# tviic2d6mddr register map
Vendor: Cypress Semiconductor; Series: tviic2d6mddr; File version: 1.0
CPU: CM7 r0p1, little endian, MPU, FPU, VTOR, 3 interrupt priority bits
Registers are 32-bit, read-write, reset 0x0 unless marked. A register's access mark holds for its fields unless they carry their own. Offsets are from the block's base; [hi:lo] are bit positions; lines under a group give offsets from that group; {n}, {i} and the like mark numbered series; 'fields as' and 'values as' point back to an identical list.

## VIDEOSS0 (part 3 of 18) — Video and Graphics Subsystem IP
Base 0x40A00000
0x00 SUBSS group — Sub Interface
  0x40000 GFX2D group — Graphics 2D Core
    0x20000 BLITENG group — Blit Engine
      0x4800 FETCHMASK group — Fetch MASK (only for IBO)
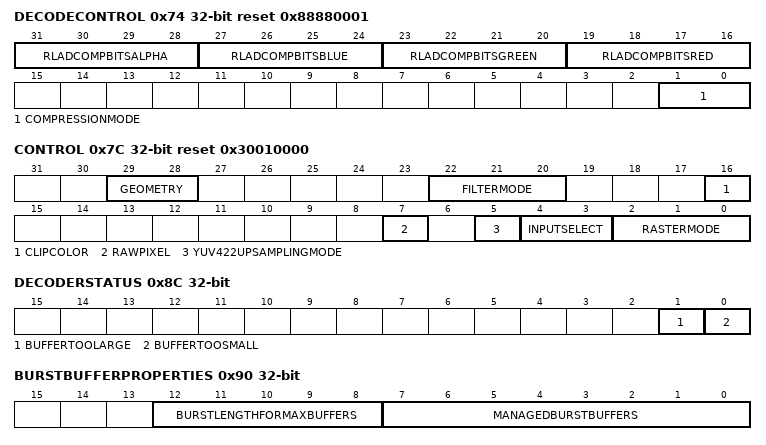
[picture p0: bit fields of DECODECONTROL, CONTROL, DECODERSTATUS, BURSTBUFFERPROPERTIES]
        0x74 DECODECONTROL reset 0x88880001 — Control options for RLAD decompression.
          [31:28] RLADCOMPBITSALPHA — Maximum for average number of bits per compressed pixel for Alpha channel. This must match the corresponding encoder setting.
          [27:24] RLADCOMPBITSBLUE — Maximum for average number of bits per compressed pixel for Blue or V (chroma) channel. This must match the corresponding encoder setting.
          [23:20] RLADCOMPBITSGREEN — Maximum for average number of bits per compressed pixel for Green or U (chroma) channel. This must match the corresponding encoder setting.
          [19:16] RLADCOMPBITSRED — Maximum for average number of bits per compressed pixel for Red or Y (luma) channel. This must match the corresponding encoder setting.
          [1:0] COMPRESSIONMODE — Algorithm that the encoder used for compression.
            0=RLAD (Run-Length Adaptive Dithering (lossy compression).); 1=RLAD_UNIFORM (Run-Length Adaptive Dithering (lossy compression; uniform package size).); 2=RLA (Run-Length Adaptive (lossless compression).); 3=RL (Standard Run-Length. In contrary to other modes is in big endian format.)
        0x78 SOURCEBUFFERLENGTH — Source buffer length for compressed data.
          [28:0] RLEWORDS — Number of 32-bit words minus one that are required to decode the run length encoded source buffer.
        0x7C CONTROL reset 0x30010000 — Shared common control settings for all layers.
          [29:28] GEOMETRY — Control the geomety settings (PerspStartX/Y/W and PerspDeltaXX/XY/YX/YY/XW/YW usage) for the raster mode PERSPECTIVE.
            0=TRANSLATE (PerspStartX/Y are used. (PerspDeltaXY/YX/XW/YW are 0. PerspDeltaXX/YY and PerspStartW are 1.)); 1=SCALE (PerspStartX/Y and PerspDeltaXX/YY are used. (PerspDeltaXY/YX/XW/YW are 0. PerspStartW is 1.)); 2=ROTATION (PerspStartX/Y and PerspDeltaXX/XY/YX/YY are used. (PerspDeltaXW/YW are 0. PerspStartW is 1.)); 3=PERSPECTIVE (All values PerspStartX/Y/W and PerspDeltaXX/XY/YX/YY/XW/YW are used)
          [22:20] FILTERMODE — Use this to select between nearest and bilinear filtering. Only has an effect if rastermode == ARBITRARY or rastermode == PERSPECTIVE or rastermode == AFFINE.
            0=NEAREST (Chooses pixel closest to sample point); 1=BILINEAR (Calculates result from 4 pixels closest to sample point); 2=FIR2 (FIR mode with 2 programmable pixel positions and coefficients); 3=FIR4 (FIR mode with 4 programmable pixel positions and coefficients); 4=HOR_LINEAR (Calculates result from 2 pixels closest to the sample point and on the same line)
          [16] CLIPCOLOR — Selects which color to take for pixels that do not lie inside the clip window of any layer.
            0=NULL (Null color.); 1=LAYER (Color of layer number given by ClipLayer (or layer 0 when Fetch unit has one layer only). The color is then the layer's source or tiling color.)
          [7] RAWPIXEL — Raw pixel mode. If enabled (value = 1), the ComponentBits/Shift settings are replaced for all layers by fixed values that allow passing the pixel data read from memory unchanged to subsequent units (e.g. for reading coordinate layers). Multiply stages and transparent color are deactivated. Skip and Tile pixels are not affected by this setting.
          [5] YUV422UPSAMPLINGMODE — Selects a method for horizontal up-sampling of YUV 422/420 input data.
            0=REPLICATE (Replicate mode for interspersed samples (UV samples between Y samples).); 1=INTERPOLATE (Interpolate mode for coaligned samples (UV samples at Y sample positions).)
          [4:3] INPUTSELECT — Selects function for the frame input port.
            0=INACTIVE (Not used.); 1=COMPPACK (Used for component packing (e.g. UV or source alpha buffer).); 2=ALPHAMASK (Used for RGB and alpha pre-multiply stage (mask alpha buffer).); 3=COORDINATE (Used for arbitrary warping (coordinate buffer).)
          [2:0] RASTERMODE — Selects a method how to generate source buffer sample points.
            0=NORMAL ([IBO only, for LBO use PERSPECTIVE with corresponding Geometry] First sample at StartX/Y relative to origin. Hor/ver increments using DeltaX/Y and DeltaSwap setup.); 1=DECODE ([FetchDecode/FetchBlit only] Source buffer is an encoded bit stream. First sample at origin (0,0). Hor/ver increments = (1,0)/(0,1).); 2=ARBITRARY ([FetchBlit/Warp only] Arbitrary warping (filter is active). Coordinates are read from frame input port. InputSelect must be set to COORDINATE. ArbStartX/Y and ArbDeltaXX/XY/YX/YY must be setup.); 3=PERSPECTIVE ([FetchBlit only] Affine/Perspective warping (filter is active). First sample at PerspStartX/Y/W. Hor/ver increments using PerspDeltaXX/XY/YX/YY/WX/WY. Homogeneous coordinates. See also field Geometry to reduce coordinate amount.); 4=YUV422 ([FetchBlit/Decode only] Source buffer is packed YUV 422. First sample at origin (0,0). Hor/ver increments = (1,0)/(0,1). All correllated window widths and horizontal offsets must be even.)
        0x80 CONTROLTRIGGER wo reset not defined — Shadow load trigger.
          [0] SHDTOKGEN — Writing a 1 to this will load shadow registers into the active configuration with the next start of frame and send a shadow load token to subsequent units.
        0x84 START wo reset not defined — Frame start trigger.
          [0] START — Writing a 1 to this field will start generating one frame (for debugging purposes only).
        0x88 FETCHTYPE ro reset not defined — Fetch unit type.
          [3:0] FETCHTYPE — This field can be used to determine what kind of fetch unit this is.
            0=DECODE (Fetch unit with RL and RLAD decoder.); 1=LAYER (Fetch unit with fractional plane (8 layers).); 2=WARP (Fetch unit with arbitrary warping and fractional plane (8 layers).); 3=ECO (Fetch unit with minimum feature set for alpha, chroma and coordinate planes.); 4=PERSP (Fetch unit with affine, perspective and arbitrary warping.); 5=ROT (Fetch unit with affine and arbitrary warping.); 6=DECODEL (Fetch unit with RL and RLAD decoder, reduced feature set.); 7=LAYERL (Fetch unit with fractional plane (8 layers), reduced feature set.); 8=ROTL (Fetch unit with affine and arbitrary warping, reduced feature set.); 9=ECOL (Fetch unit with reduced minimum feature set for alpha, chroma and coordinate planes.); 10=BLIT (Fetch unit with DECODE and PERSP capabilities.)
        0x8C DECODERSTATUS — Status information of the RLAD decoder.
          [1] BUFFERTOOLARGE — The buffer size given by RLEWords is too large. A complete output frame could be decoded, but more data was read than necessary.
          [0] BUFFERTOOSMALL — The buffer size given by RLEWords is too small. No complete output frame could be decoded.
        0x90 BURSTBUFFERPROPERTIES ro reset not defined
          [12:8] BURSTLENGTHFORMAXBUFFERS — Maximum Burst Length that can be used when ManagedBurstBuffers burst buffers are used.
          [7:0] MANAGEDBURSTBUFFERS — Maximum number of burst buffers that can be administrated in the AXI interface.
      0x5000 ROP group
        0x00 STATICCONTROL — Raster Operation static control register
          [0] SHDEN — Enables shadowing of all RWS type registers (0=write_through, 1=shadowed).
        0x04 CONTROL — Raster Operation control register
          [10] TERTDIV2 — Selects whether to divide the tertiary input color components by two or not for ADD mode. This field has no effect on a color component in ROP mode.
            0=BYPASS (No change to input); 1=DIVIDEBY2 (Input is divided by two/shift to the right by one)
          [9] SECDIV2 — Selects whether to divide the secondary input color components by two or not for ADD mode. This field has no effect on a color component in ROP mode.
            values as TERTDIV2
          [8] PRIMDIV2 — Selects whether to divide the primary input color components by two or not for ADD mode. This field has no effect on a color component in ROP mode.
            values as TERTDIV2
          [7] REDMODE — Selects the mode for the red component channel, has no effect in NEUTRAL mode
            0=ROP (Normal raster operation mode, using the operation index); 1=ADD (Add mode, adds this component from all enabled inputs, clamps to 1)
          [6] GREENMODE — Selects the mode for the green component channel, has no effect in NEUTRAL mode
            values as REDMODE
          [5] BLUEMODE — Selects the mode for the blue component channel, has no effect in NEUTRAL mode
            values as REDMODE
          [4] ALPHAMODE — Selects the mode for the alpha component channel, has no effect in NEUTRAL mode
            values as REDMODE
          [0] MODE — Operation mode for rop
            0=NEUTRAL (Neutral mode); 1=OPERATION (Normal Operation)
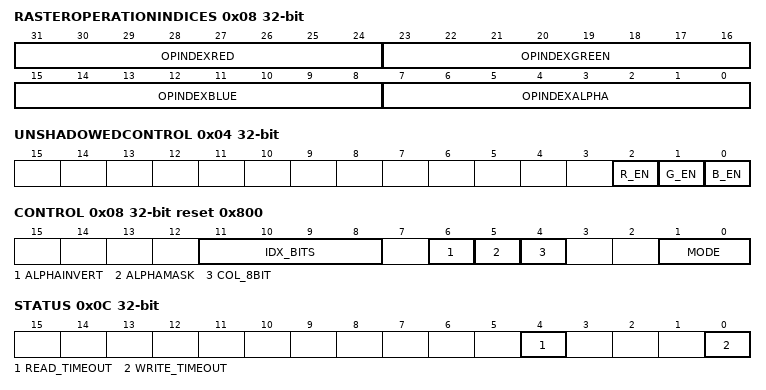
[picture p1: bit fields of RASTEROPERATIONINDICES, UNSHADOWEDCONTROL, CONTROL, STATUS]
        0x08 RASTEROPERATIONINDICES — ROP operation indices
          [31:24] OPINDEXRED — Red operation index
          [23:16] OPINDEXGREEN — Green operation index
          [15:8] OPINDEXBLUE — Blue operation index
          [7:0] OPINDEXALPHA — Alpha operation index
        0x0C PRIMCONTROLWORD ro reset not defined — Value of last received primary control word
          [31:0] P_VAL — Value of last received control word on the primary input. If a 39 bit pixel channel is connected, the mapping is as follows: p_val[31:0] = { data[37:22], data[19:12], data[9:2] }. For debug purposes only, read when stable only, otherwise read data might be corrupted.
        0x10 SECCONTROLWORD ro reset not defined — Value of last received secondary control word
          [31:0] S_VAL — Value of last received control word on the secondary input. If a 39 bit pixel channel is connected, the mapping is as follows: s_val[31:0] = { data[37:22], data[19:12], data[9:2] }. For debug purposes only, read when stable only, otherwise read data might be corrupted.
        0x14 TERTCONTROLWORD ro reset not defined — Value of last received tertiary control word
          [31:0] T_VAL — Value of last received control word on the tertiary input. If a 39 bit pixel channel is connected, the mapping is as follows: t_val[31:0] = { data[37:22], data[19:12], data[9:2] }. For debug purposes only, read when stable only, otherwise read data might be corrupted.
      0x5800 CLUT group — CLut (only for IBO)
        0x00 STATICCONTROL — CLUT static control register
          fields as SUBSS.GFX2D.BLITENG.ROP.STATICCONTROL
        0x04 UNSHADOWEDCONTROL — CLUT unshadowed control register
          [all] fields
            0=DISABLE; 1=ENABLE
          [2] R_EN — Write enable for writing the red color LUT entry from the host (allows writing a single color entry without a read-modify-write cycle)
          [1] G_EN — Write enable for writing the green color LUT entry from the host (allows writing a single color entry without a read-modify-write cycle)
          [0] B_EN — Write enable for writing the blue color LUT entry from the host (allows writing a single color entry without a read-modify-write cycle)
        0x08 CONTROL reset 0x800 — CLUT control register
          [11:8] IDX_BITS — Number of msb bits of the red color input used for the LUT index input
          [6] ALPHAINVERT — Chooses whether to disable lookup for alpha components smaller or greater/equal than 128. For this field to have an effect AlphaMask must be set to ENABLE.
            0=NORMAL (Disable computation for alpha smaller than 128); 1=INVERT (Disable computation for alpha greater than or equal to 128)
          [5] ALPHAMASK — Enables the alpha mask mode. This mode disables lookup for all pixels with an alpha component smaller or greater/equal than 128. They are bypassed unchanged.
            0=DISABLE (Alpha mask mode disabled); 1=ENABLE (Alpha mask mode enabled)
          [4] COL_8BIT — Color (red, green, blue) output bitwidth select
            0=DISABLE (color is 10bit output); 1=ENABLE (color is 8bit output (dithering of internal 10bit value))
          [1:0] MODE — Operation mode for color lookup table
            0=NEUTRAL (module in neutral mode, input data is bypassed to the output); 1=LUT (module in color lookup mode (LUT holds a 10bit color value lookup value for each input color)); 2=INDEX_10BIT (module in 10bit color index table mode (LUT holds a 3x10bit color value, indexed with the red input color)); 3=INDEX_RGBA (module in RGBA color index table mode (LUT holds a 3x8bit color value and a 6bit alpha value, indexed with the red input color))
        0x0C STATUS — CLUT status register
          [4] READ_TIMEOUT — Timeout detected when reading from the LUT
          [0] WRITE_TIMEOUT — Timeout detected when writing to the LUT
        0x10 LASTCONTROLWORD ro reset not defined — Value of last received control word, for debugging
          [31:0] L_VAL — Value of last received control word. For debug purposes only, read when stable only, otherwise read data might be corrupted.
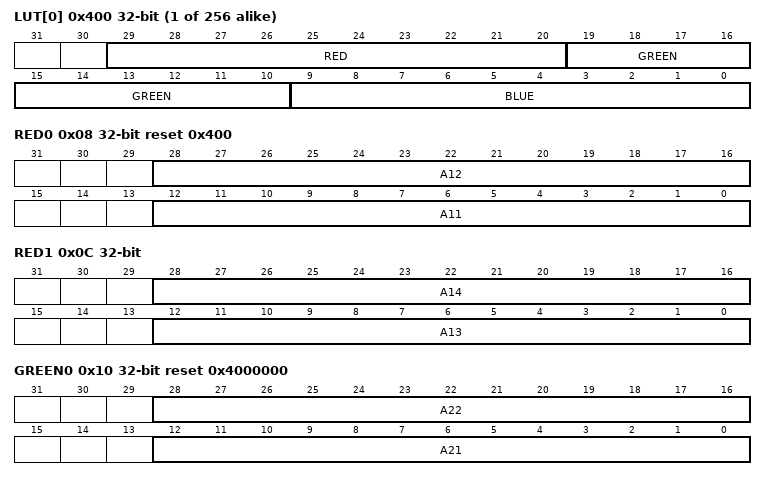
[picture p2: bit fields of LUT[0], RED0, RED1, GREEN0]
        {0x400+4m} LUT[{m}] (m=0..255) reset not defined — Look Up Table
          [29:20] RED — Red component
          [19:10] GREEN — Green component
          [9:0] BLUE — Blue component
      0x6000 MATRIX group
        0x00 STATICCONTROL — Color Matrix static control register
          fields as SUBSS.GFX2D.BLITENG.ROP.STATICCONTROL
        0x04 CONTROL — Color Matrix control register
          [5] ALPHAINVERT — Value 1 inverts the effect of the alpha mask mode when enabled (pixels with alpha value greater or equal 0.5 are by-passed).
          [4] ALPHAMASK — Value 1 enables the alpha mask mode. In this mode all pixels with an alpha value smaller than 0.5 are by-passed unchanged.
          [1:0] MODE — Operation mode for color matrix
            0=NEUTRAL (Module in neutral mode, input data is bypassed); 1=MATRIX (Module in matrix mode, input data is multiplied with matrix values); 2=PREMUL (Module in alpha pre-multiplication mode, input color is multiplied with input alpha); 3=RSVD (N/A)
        0x08 RED0 reset 0x400 — Matrix values for calculation of the red output value.
          [28:16] A12 — Value for green input. (format is signed fix-point 3.10)
          [12:0] A11 — Value for red input. (format is signed fix-point 3.10)
        0x0C RED1 — Matrix values for calculation of the red output value.
          [28:16] A14 — Value for alpha input. (format is signed fix-point 3.10)
          [12:0] A13 — Value for blue input. (format is signed fix-point 3.10)
        0x10 GREEN0 reset 0x4000000 — Matrix values for calculation of the green output value.
          [28:16] A22 — Value for green input. (format is signed fix-point 3.10)
          [12:0] A21 — Value for red input. (format is signed fix-point 3.10)
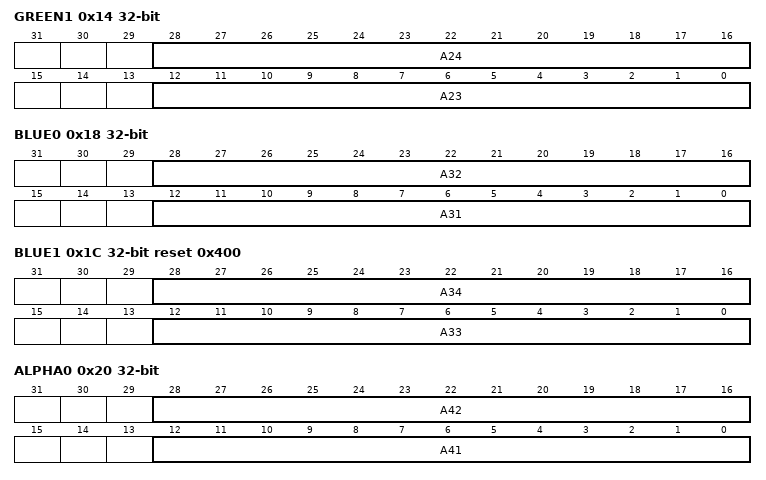
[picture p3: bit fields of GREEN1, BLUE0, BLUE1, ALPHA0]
        0x14 GREEN1 — Matrix values for calculation of the green output value.
          [28:16] A24 — Value for alpha input. (format is signed fix-point 3.10)
          [12:0] A23 — Value for blue input. (format is signed fix-point 3.10)
        0x18 BLUE0 — Matrix values for calculation of the blue output value.
          [28:16] A32 — Value for green input. (format is signed fix-point 3.10)
          [12:0] A31 — Value for red input. (format is signed fix-point 3.10)
        0x1C BLUE1 reset 0x400 — Matrix values for calculation of the blue output value.
          [28:16] A34 — Value for alpha input. (format is signed fix-point 3.10)
          [12:0] A33 — Value for blue input. (format is signed fix-point 3.10)
        0x20 ALPHA0 — Matrix values for calculation of the alpha output value.
          [28:16] A42 — Value for green input. (format is signed fix-point 3.10)
          [12:0] A41 — Value for red input. (format is signed fix-point 3.10)
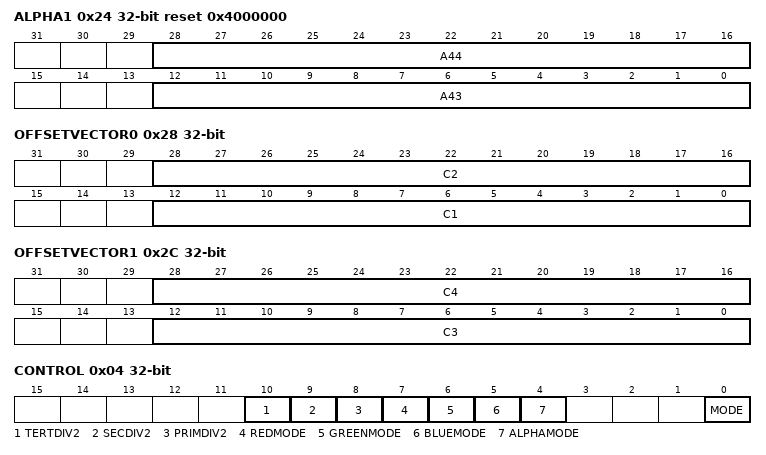
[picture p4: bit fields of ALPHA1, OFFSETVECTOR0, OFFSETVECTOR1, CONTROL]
        0x24 ALPHA1 reset 0x4000000 — Matrix values for calculation of the alpha output value.
          [28:16] A44 — Value for alpha input. (format is signed fix-point 3.10)
          [12:0] A43 — Value for blue input. (format is signed fix-point 3.10)
        0x28 OFFSETVECTOR0 — Offset vectors for red and green output.
          [28:16] C2 — Green output offset. (format is signed integer)
          [12:0] C1 — Red output offset. (format is signed integer)
        0x2C OFFSETVECTOR1 — Offset vectors for blue and alpha output.
          [28:16] C4 — Alpha output offset. Note that the 8-bit alpha input is up-scaled to 10-bit, before the matrix and this offset is applied, and down-scaled to 8-bit for output afterwards. (format is signed integer)
          [12:0] C3 — Blue output offset. (format is signed integer)
      0x6400 GPSCALER group — GPScaler (only for IBO)
        0x00 STATICCONTROL — Static control settings that must typically be setup once only.
          [0] SHDEN — If ShdEn==1 shadow registers are loaded when indicated by hardware signal ( a command signal in the data stream at frame start ). If ShdEn==0 shadow registers are loaded each frame start. (format is unsigned integer)
        0x04 CONTROL — Global operation control.
          [8] OPERATION_MODE — Selects the kind of operation to execute. (format is unsigned integer)
            0=SCALE (Scaler is active with the corresponding settings from scaler registers; filter registers are ignored.); 1=FIR (FIR-Filter is active with the corresponding settings from filter registers; scaler registers are ignored.)
          [3:0] MODE — Controls the sequence of horizontal and vertical operation for all operation modes. (format is unsigned integer)
            0=NEUTRAL (Neutral mode. Pixels are by-passed unchanged, all other settings are ignored.); 14=ACTIVE_AUTO (Automatic mode. Behaves like ACTIVE_VER_FIRST when operation_mode=SCALE and scale_mode_h=UPSCALE, like ACTIVE_HOR_FIRST otherwise.); 12=ACTIVE_HOR_FIRST (Horizontal is done before vertical operation.); 13=ACTIVE_VER_FIRST (Vertical is done before horizontal operation.); 8=ACTIVE_HOR_ONLY (Only horizontal operation is done.); 5=ACTIVE_VER_ONLY (Only vertical operation is done.)
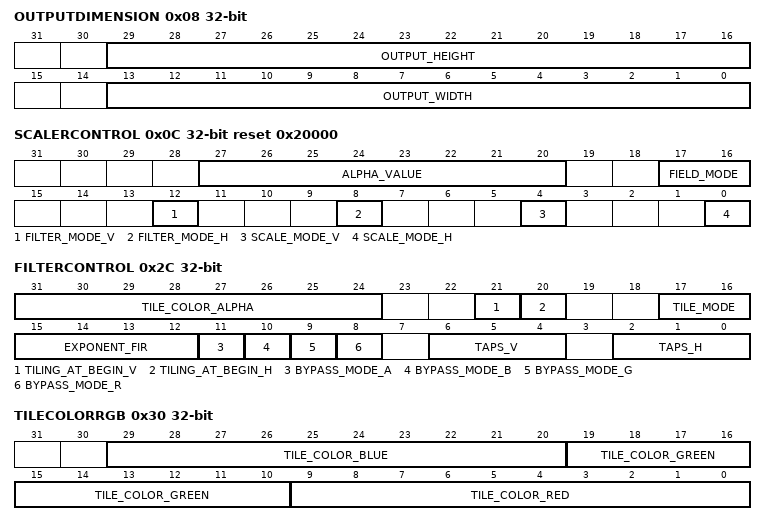
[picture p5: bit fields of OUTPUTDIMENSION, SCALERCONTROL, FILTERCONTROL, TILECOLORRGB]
        0x08 OUTPUTDIMENSION — Dimensions of the output frame or fame slice. This values are required for both FIR filter and scaler, since their output may have other dimension than input. The dimension of scaler's output is defined by the scale factor. The dimension of FIR filter's output depends on the tiling at the begin and the end of the slice.
          [29:16] OUTPUT_HEIGHT — Number of output lines per input frame or slice. This number is equal to the height of the output frame minus one. (format is unsigned integer)
          [13:0] OUTPUT_WIDTH — Number of output pixel per input line. This number is equal to the width of the output frame minus one. (format is unsigned integer)
        0x0C SCALERCONTROL reset 0x20000 — Scaler operation control.
          [27:20] ALPHA_VALUE — When 'mode' field is not 'NEUTRAL', then input alpha values are ignore and output alpha set to this constant value for all pixels. This restriction applies to GPScalerL derivative only. (format is unsigned integer)
          [17:16] FIELD_MODE — Controls generation of output field polarity for vertical scaling. (format is unsigned integer)
            0=ALWAYS0 (Constant 0 indicates frame or top field.); 1=ALWAYS1 (Constant 1 indicates bottom field.); 2=INPUT (Output field polarity is taken from input field polarity.); 3=TOGGLE (Output field polarity toggles, starting with 0 after reset.)
          [12] FILTER_MODE_V — Selects sampling algorithm for vertical scaling. (format is unsigned integer)
            0=NEAREST (Nearest filter (point-sampling)); 1=LINEAR (Box filter (linear))
          [8] FILTER_MODE_H — Selects sampling algorithm for horizontal scaling. (format is unsigned integer)
            values as FILTER_MODE_V
          [4] SCALE_MODE_V — Scale mode for vertical scaling. (format is unsigned integer)
            0=DOWNSCALE (Down-scaling (output height less or equal input height).); 1=UPSCALE (Up-scaling (output height greater or equal input height))
          [0] SCALE_MODE_H — Scale mode for horizontal scaling. (format is unsigned integer)
            0=DOWNSCALE (Down-scaling (output width is less or equal input width).); 1=UPSCALE (Up-scaling (output width greater or equal input width))
        0x10 SCALERSETUPH0 reset 0x80000 — Phase interpolator setup.
          [19:0] SCALE_FACTOR_H — Scale factor has to be greater than 0.0 and less than or equal to 1.0. If scale_mode is UPSCALE then the inverse scale factor has to be programmed. (format is unsigned fix-point 1.19)
        0x14 SCALERSETUPH1 — Phase interpolator setup.
          [20:0] PHASE_OFFSET_H — Phase offset has to be larger than -2 and smaller than +2. Depending on scale_mode this value is relative to input (UPSCALE) or output pixel (DOWNSCALE). A negative value shifts the image to the right, a positive one to the left. (format is signed fix-point 2.19)
        0x18 SCALERSETUPV0 reset 0x80000 — Phase interpolator setup.
          [19:0] SCALE_FACTOR_V — Scale factor is greater than 0.0 and less than or equal to 1.0. If scale_mode is UPSCALE then the inverse scale factor have to be programmed. (format is unsigned fix-point 1.19)
        0x1C SCALERSETUPV1 — Phase interpolator setup, selected if input and output field polarity is 0.
          [20:0] PHASE_OFFSET_V — Phase offset has to be larger than -2 and smaller than +2. Depending on scale_mode this value is relative to input (UPSCALE) or output pixel (DOWNSCALE). A negative value shifts the image to the bottom, a positive one to the top. (format is signed fix-point 2.19)
        0x20 SCALERSETUPV2 — Phase interpolator setup, selected if input field polarity is 1 and output field polarity is 0.
          [20:0] PHASE_OFFSET_V1 — Phase offset has to be larger than -2 and smaller than +2. Depending on scale_mode this value is relative to input (UPSCALE) or output pixel (DOWNSCALE). A negative value shifts the image to the bottom, a positive one to the top. (format is signed fix-point 2.19)
        0x24 SCALERSETUPV3 — Phase interpolator setup, selected if input field polarity is 0 and output field polarity is 1.
          [20:0] PHASE_OFFSET_V2 — Phase offset has to be larger than -2 and smaller than +2. Depending on scale_mode this value is relative to input (UPSCALE) or output pixel (DOWNSCALE). A negative value shifts the image to the bottom, a positive one to the top. (format is signed fix-point 2.19)
        0x28 SCALERSETUPV4 — Phase interpolator setup, selected if input and output field polarity is 1.
          [20:0] PHASE_OFFSET_V3 — Phase offset has to be larger than -2 and smaller than +2. Depending on scale_mode this value is relative to input (UPSCALE) or output pixel (DOWNSCALE). A negative value shifts the image to the bottom, a positive one to the top. (format is signed fix-point 2.19)
        0x2C FILTERCONTROL — Filter operation control.
          [31:24] TILE_COLOR_ALPHA — Sets the alpha value for pixels outside of the slice. (format is unsigned integer)
          [21] TILING_AT_BEGIN_V — If set to true, this bit enables tiling at the begin of the slice for vertical direction. Tiling at the end occurs automatically by setting the corresponding output size. (format is unsigned integer)
          [20] TILING_AT_BEGIN_H — If set to true, this bit enables tiling at the begin of the slice for horizontal direction. Tiling at the end occurs automatically by setting the corresponding output size. (format is unsigned integer)
          [17:16] TILE_MODE — Selects the tile mode for pixels outside the source frame. In order to enable tiling tiling_at_begin_h or tiling_at_begin_v and the corresponding output frame dimension have to be set. (format is unsigned integer)
            0=TILE_FILL_ZERO (Use zero value.); 1=TILE_FILL_CONSTANT (Use constant color value from the field tile_color.); 2=TILE_PAD (Use closest pixel from source frame.); 3=TILE_PAD_ZERO (Use closest pixel from source buffer but zero for alpha component.)
          [15:12] EXPONENT_FIR — FIR product sum is divided by 2**FIR_exponent and rounded. (format is unsigned integer)
          [11] BYPASS_MODE_A — Bypass configuration for alpha components of every pixel. (format is unsigned integer)
            0=NEUTRAL (Alpha is filtered.); 1=ACTIVE (Alpha is not filtered, but is written to the line buffer.)
          [10] BYPASS_MODE_B — Bypass configuration for blue color components of every pixel. (format is unsigned integer)
            0=NEUTRAL (Blue color is filtered.); 1=ACTIVE (Blue color is not filtered, but is written to the line buffer.)
          [9] BYPASS_MODE_G — Bypass configuration for green color components of every pixel. (format is unsigned integer)
            0=NEUTRAL (Green color is filtered.); 1=ACTIVE (Green color is not filtered, but is written to the line buffer.)
          [8] BYPASS_MODE_R — Bypass configuration for red color components of every pixel. (format is unsigned integer)
            0=NEUTRAL (Red color is filtered.); 1=ACTIVE (Red color is not filtered, but is written to the line buffer.)
          [6:4] TAPS_V — Defines the vertical size of the FIR filter between 1 and 15 with increment of 2. Only odd filter width is supported. To program this field following formula has to be used: (filter height - 1)/2 (format is unsigned integer)
          [2:0] TAPS_H — Defines the horizontal size of the FIR filter between 1 and 15 with increment of 2. Only odd filter width is supported. To program this field following formula has to be used: (filter width - 1)/2 (format is unsigned integer)
        0x30 TILECOLORRGB — Color for outside of the slice.
          [29:20] TILE_COLOR_BLUE — Sets the blue color value for pixels outside of the slice. (format is unsigned integer)
          [19:10] TILE_COLOR_GREEN — Sets the green color value for pixels outside of the slice. (format is unsigned integer)
          [9:0] TILE_COLOR_RED — Sets the red color value for pixels outside of the slice. (format is unsigned integer)
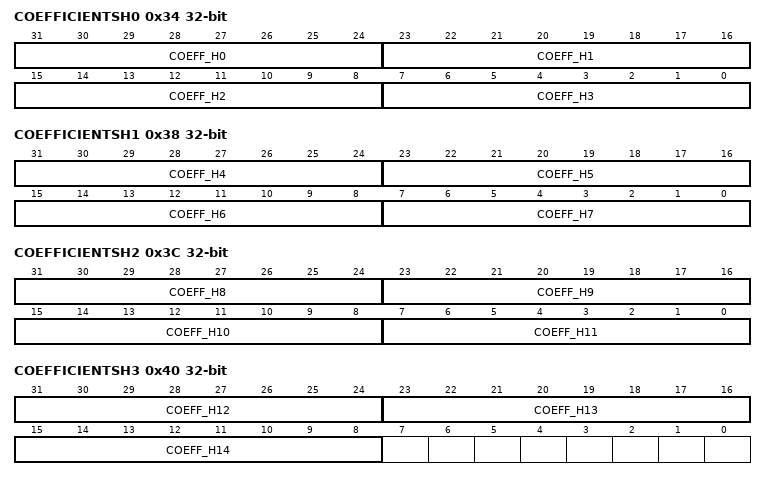
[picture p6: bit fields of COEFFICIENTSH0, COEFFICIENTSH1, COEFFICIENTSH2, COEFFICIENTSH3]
        0x34 COEFFICIENTSH0 — Horizontal coefficients for filter_mode FIR.
          [31-8n:24-8n] COEFF_H{n} (n=0..3) — Horizontal coefficient {n}. (format is signed integer)
        0x38 COEFFICIENTSH1 — Horizontal coefficients for filter_mode FIR.
          [63-8n:56-8n] COEFF_H{n} (n=4..7) — Horizontal coefficient {n}. (format is signed integer)
        0x3C COEFFICIENTSH2 — Horizontal coefficients for filter_mode FIR.
          [95-8n:88-8n] COEFF_H{n} (n=8..11) — Horizontal coefficient {n}. (format is signed integer)
        0x40 COEFFICIENTSH3 — Horizontal coefficients for filter_mode FIR.
          [31:24] COEFF_H12 — Horizontal coefficient 12. (format is signed integer)
          [23:16] COEFF_H13 — Horizontal coefficient 13. (format is signed integer)
          [15:8] COEFF_H14 — Horizontal coefficient 14. The rightmost coefficient regardless of the filter width. In contrast to the coeff_h0 this coefficient has to be always programmed. (format is signed integer)
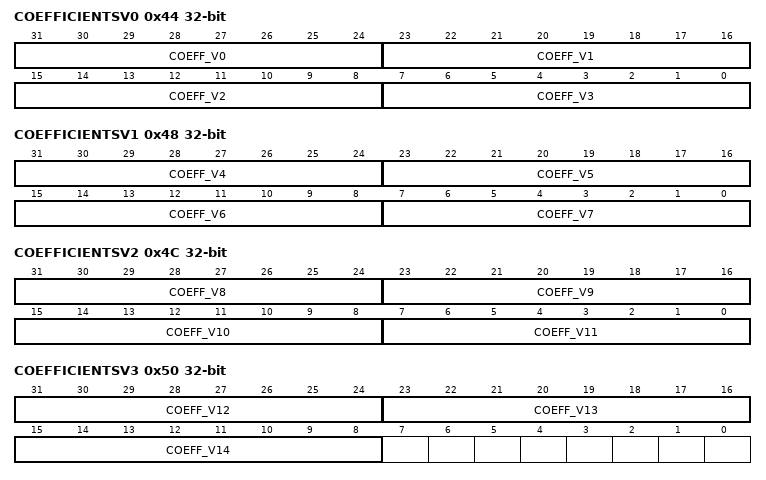
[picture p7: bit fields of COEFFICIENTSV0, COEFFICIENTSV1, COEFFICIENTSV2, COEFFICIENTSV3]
        0x44 COEFFICIENTSV0 — Vertical coefficients for filter_mode FIR.
          [31-8n:24-8n] COEFF_V{n} (n=0..3) — Vertical coefficient {n}. (format is signed integer)
        0x48 COEFFICIENTSV1 — Vertical coefficients for filter_mode FIR.
          [63-8n:56-8n] COEFF_V{n} (n=4..7) — Vertical coefficient {n}. (format is signed integer)
        0x4C COEFFICIENTSV2 — Vertical coefficients for filter_mode FIR.
          [95-8n:88-8n] COEFF_V{n} (n=8..11) — Vertical coefficient {n}. (format is signed integer)
        0x50 COEFFICIENTSV3 — Vertical coefficients for filter_mode FIR.
          [31:24] COEFF_V12 — Vertical coefficient 12. (format is signed integer)
          [23:16] COEFF_V13 — Vertical coefficient 13. (format is signed integer)
          [15:8] COEFF_V14 — Vertical coefficient 14. The bottommost coefficient regardless of the filter height. In contrast to the coeff_v0 this coefficient has to be always programmed. (format is signed integer)
      0x6800 BLITBLEND group
        0x00 STATICCONTROL — BlitBlend static control register
          fields as SUBSS.GFX2D.BLITENG.ROP.STATICCONTROL
        0x04 CONTROL — BlitBlend control register
          [0] MODE — Operation mode for BlitBlend
            0=NEUTRAL (Neutral mode, only route pixels and commands from primary input to output); 1=OPERATION (Normal Operation)
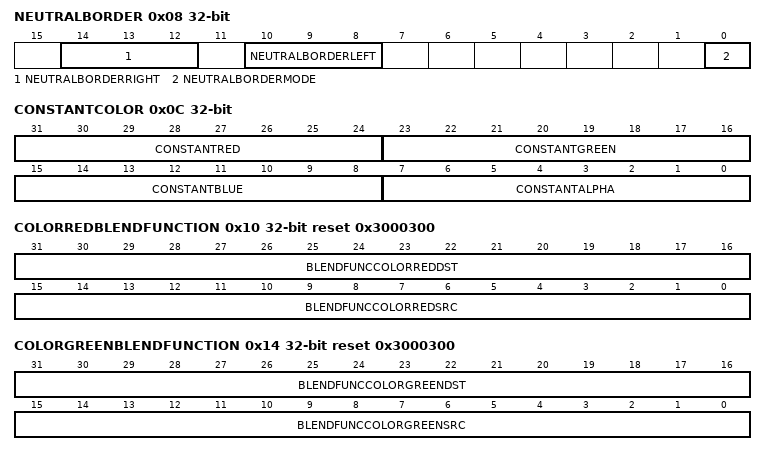
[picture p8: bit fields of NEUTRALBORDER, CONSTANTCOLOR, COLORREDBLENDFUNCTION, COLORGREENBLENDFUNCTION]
        0x08 NEUTRALBORDER — Neutral border setup register
          [14:12] NEUTRALBORDERRIGHT — Number of neutral right border pixels
          [10:8] NEUTRALBORDERLEFT — Number of neutral left border pixels
          [0] NEUTRALBORDERMODE — Chooses whether to bypass primary or secondary input pixels
            0=PRIMARY (Bypasses primary pixel); 1=SECONDARY (Bypasses secondary pixel)
        0x0C CONSTANTCOLOR
          [31:24] CONSTANTRED — Red and Y (luma).
          [23:16] CONSTANTGREEN — Green and U (chroma).
          [15:8] CONSTANTBLUE — Blue and V (chroma).
          [7:0] CONSTANTALPHA — Alpha.
        0x10 COLORREDBLENDFUNCTION reset 0x3000300 — Open GL RGB blending factors
          [31:16] BLENDFUNCCOLORREDDST — Red component destination blend function
          [15:0] BLENDFUNCCOLORREDSRC — Red component source blend function
        0x14 COLORGREENBLENDFUNCTION reset 0x3000300 — Open GL RGB blending factors
          [31:16] BLENDFUNCCOLORGREENDST — Green component destination blend function
          [15:0] BLENDFUNCCOLORGREENSRC — Green component source blend function
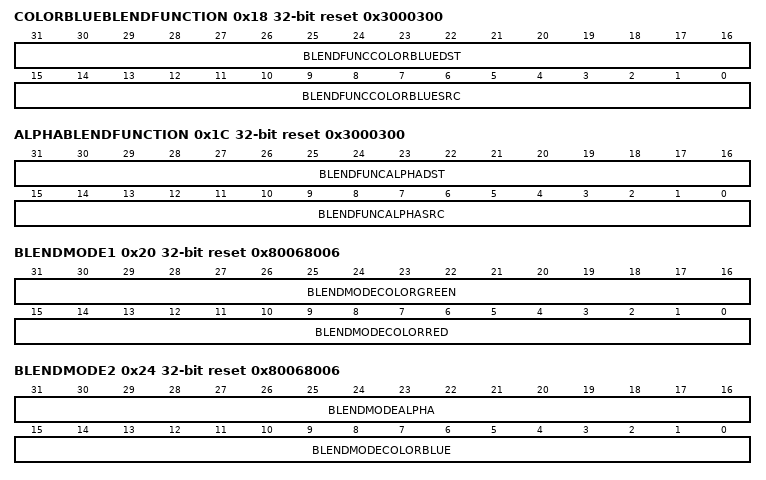
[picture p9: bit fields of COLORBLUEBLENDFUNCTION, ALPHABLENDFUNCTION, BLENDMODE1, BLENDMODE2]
        0x18 COLORBLUEBLENDFUNCTION reset 0x3000300 — Open GL RGB blending factors
          [31:16] BLENDFUNCCOLORBLUEDST — Blue component destination blend function
          [15:0] BLENDFUNCCOLORBLUESRC — Blue component source blend function
        0x1C ALPHABLENDFUNCTION reset 0x3000300 — Open GL alpha blending factors
          [31:16] BLENDFUNCALPHADST — Alpha component destination blend function
          [15:0] BLENDFUNCALPHASRC — Alpha component source blend function
        0x20 BLENDMODE1 reset 0x80068006 — Open GL and Open VG blending modes for colors red and green
          [31:16] BLENDMODECOLORGREEN — Green component blend mode
          [15:0] BLENDMODECOLORRED — Red component blend mode
        0x24 BLENDMODE2 reset 0x80068006 — Open GL and Open VG blending modes for color blue and alpha
          [31:16] BLENDMODEALPHA — Alpha component blend mode
          [15:0] BLENDMODECOLORBLUE — Blue component blend mode
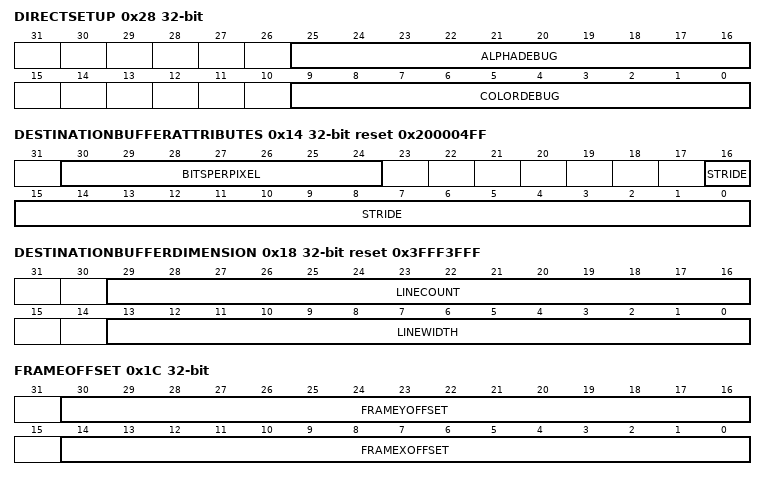
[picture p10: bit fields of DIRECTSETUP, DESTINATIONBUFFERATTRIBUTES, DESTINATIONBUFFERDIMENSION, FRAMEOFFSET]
        0x28 DIRECTSETUP — Direct Control of the BlitBlend Datapath multiplexers, do not change
          [25:16] ALPHADEBUG — Sets the multiplexers of the alpha datapath directly, do not change
          [9:0] COLORDEBUG — Sets the multiplexers of the color datapath directly, do not change
        0x2C PRIMCONTROLWORD ro reset not defined — Value of last received primary control word
          [31:0] P_VAL — Value of last received control word on primary input. If a 39 bit pixel channel is connected, the mapping is as follows: p_val[31:0] = { data[37:22], data[19:12], data[9:2] }. For debug purposes only, read when stable only, otherwise read data might be corrupted.
        0x30 SECCONTROLWORD ro reset not defined — Value of last received secondary control word
          [31:0] S_VAL — Value of last received control word on secondary input. If a 39 bit pixel channel is connected, the mapping is as follows: s_val[31:0] = { data[37:22], data[19:12], data[9:2] }. For debug purposes only, read when stable only, otherwise read data might be corrupted.
      0x6C00 STORE group
        0x00 STATICCONTROL — Store unit static control register.
          [8] BASEADDRESSAUTOUPDATE — If enabled (value 1) the base address is automatically updated at the start of each frame. This update is then executed independently of the ShdEn setting. When disabled ShdEn controls the update of the base address operation register.
          [4] SINGLEFRAMEOPERATION — If this field and ShdEn are enabled, only frames with reload bit in command word are written to AXI, other frames are still consumed. If disabled all frames are writen to AXI
          [0] SHDEN — Enables shadowing of all RWS type registers (0=write_through, 1=shadowed).
        0x04 BURSTBUFFERMANAGEMENT reset 0x400 — Burst Buffer setup register.
          [12:8] SETBURSTLENGTH — Set this to the burst length that should be used on the AXI interface. Please note that SetBurstLength has to be smaller or equal to MaxBurstLength. Only a power of two may be specified as burst length. Please set this to at least 2 for 64bit pixels, otherwise performance will suffer.
        0x08 RINGBUFSTARTADDR — Ring buffer setup for destination.
          [31:0] RINGBUFSTARTADDR — Start address of the ring buffer. Must be aligned to SetBurstLength x 8 bytes.
        0x0C RINGBUFWRAPADDR — Ring buffer setup for destination.
          [31:0] RINGBUFWRAPADDR — End address of the ring buffer (last byte of the buffer plus one).
        0x10 BASEADDRESS — Destination buffer base address.
          [31:0] BASEADDRESS — Byte aligned start address of the destination buffer. For 32 bit pixels BaseAddress[1:0] must be set 0 and for 16 bit pixels BaseAddress[0] must be set 0.
        0x14 DESTINATIONBUFFERATTRIBUTES reset 0x200004FF
          [30:24] BITSPERPIXEL — Size of a pixel in the destination buffer in bits. Has to be a power of two, 18 or 24. When 64 bit is selected, input pixels are converted into a 32 bit value that is replicated into low and high word of the 64 bit output. Set SetBurstLength at least to 2 in that case to get best possible performance.
          [16:0] STRIDE — Destination buffer stride in bytes minus one, used for address generation. For a pixel width of 32 bits Stride has to be dividable by 4 and given minus one and for a pixel width of 16 bit Stride has to be dividable by two and given minus one.
        0x18 DESTINATIONBUFFERDIMENSION reset 0x3FFF3FFF
          [29:16] LINECOUNT — Number of lines of the destination buffer in pixels minus one.
          [13:0] LINEWIDTH — Width of the destination buffer in pixels minus one.
        0x1C FRAMEOFFSET — Offset between destination frame and buffer.
          [30:16] FRAMEYOFFSET — Vertical offset (Y). (format is signed integer)
          [14:0] FRAMEXOFFSET — Horizontal offset (X). FrameXOffset * BitsPerPixel must be byte aligned. The same applies to the Store unit's input frame width * BitsPerPixel. (format is signed integer)
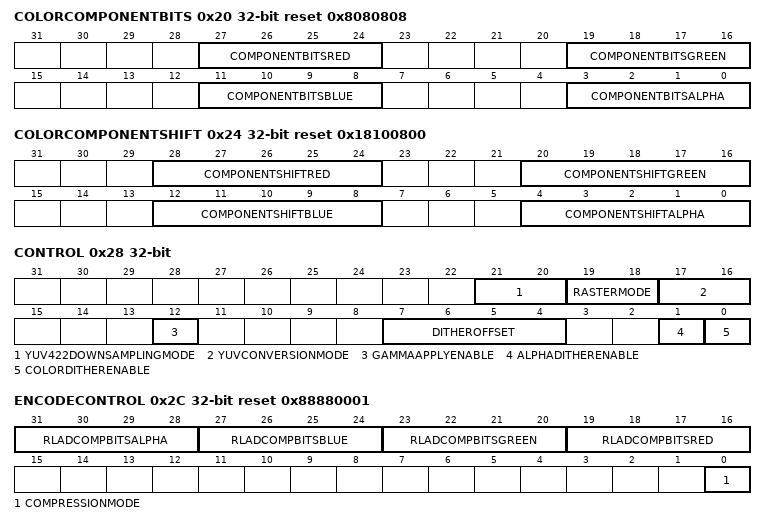
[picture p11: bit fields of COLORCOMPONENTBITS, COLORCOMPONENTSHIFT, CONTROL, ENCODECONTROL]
        0x20 COLORCOMPONENTBITS reset 0x8080808 — Color component size of destination buffer
          [27:24] COMPONENTBITSRED — Red/Y component bits.
          [19:16] COMPONENTBITSGREEN — Green/U component bits.
          [11:8] COMPONENTBITSBLUE — Blue/V component bits.
          [3:0] COMPONENTBITSALPHA — Alpha component bits.
        0x24 COLORCOMPONENTSHIFT reset 0x18100800 — Color component offset of destination buffer.
          [28:24] COMPONENTSHIFTRED — Red/Y component shift.
          [20:16] COMPONENTSHIFTGREEN — Green/U component shift.
          [12:8] COMPONENTSHIFTBLUE — Blue/V component shift.
          [4:0] COMPONENTSHIFTALPHA — Alpha component shift.
        0x28 CONTROL — Store unit dynamic control register
          [21:20] YUV422DOWNSAMPLINGMODE — Selects a method for horizontal down-sampling when RasterMode is YUV422.
            0=NEAREST (Nearest mode. Discards all odd samples, outputs even samples.); 1=COALIGNED (Linear coaligned mode. 3 nearest UV samples are combined in linear filter to get one output sample.); 2=INTERSPERSED (Linear interspersed mode. 2 nearest UV samples are combined in linear filter to get one output sample.)
          [19:18] RASTERMODE — Selects a method for destination buffer data from input pixels.
            0=NORMAL (RGBA or YUV 4:4:4 pixel buffer.); 1=YUV422 (Packed YUV 4:2:2 pixel buffer. Effect is that U samples are written for pixels with even and V samples for odd column index only. So BitsPerPixel must be set to the size that a pair of YU or YV has in memory (most typically 16 bits). All correlated widths and horizontal offsets must be even.); 2=ENCODE (RLAD compressed bit stream.)
          [17:16] YUVCONVERSIONMODE — Enables different kind of RGB to YUV conversions.
            0=OFF (No conversion. Input data must be RGB.); 1=ITU601 (Conversion from YCbCr (YUV) to RGB according to ITU recommendation BT.601-6 (standard definition TV). Input range is 16..235 for Y and 16..240 for U/V.); 2=ITU601_FR (Conversion from YCbCr (YUV) to RGB according to ITU recommendation BT.601-6, but assuming full range YUV inputs (0..255). Most typically used for computer graphics (e.g. for JPEG encoding).); 3=ITU709 (Conversion from YCbCr (YUV) to RGB according to ITU recommendation BT.709-5 part 2 (high definition TV). Input range is 16..235 for Y and 16..240 for U/V.)
          [12] GAMMAAPPLYENABLE — Enable gamma conversion stage to apply gamma function. This gamma function converts the pixel data from linear color space to non-linear color space before writing it to AXI.
          [7:4] DITHEROFFSET — Dither offset that is additionally applied to the spatial offset, which is internally generated from the pixel position. Can be used by SW to generate image sequences with temporal dithering.
          [1] ALPHADITHERENABLE — Controls whether spatial dithering (value 1) or LSB truncation (value 0) is used when ComponentBitsAlpha is smaller than 8 bits.
          [0] COLORDITHERENABLE — Controls whether spatial dithering (value 1) or LSB truncation (value 0) is used when ComponentBitsRed/Green/Blue is smaller than 10 bits.
        0x2C ENCODECONTROL reset 0x88880001 — Control options for RLAD compression.
          [31:28] RLADCOMPBITSALPHA — Maximum for average number of bits per compressed pixel for Alpha channel.
          [27:24] RLADCOMPBITSBLUE — Maximum for average number of bits per compressed pixel for Blue or V (chroma) channel.
          [23:20] RLADCOMPBITSGREEN — Maximum for average number of bits per compressed pixel for Green or U (chroma) channel.
          [19:16] RLADCOMPBITSRED — Maximum for average number of bits per compressed pixel for Red or Y (luma) channel.
          [0] COMPRESSIONMODE — Algorithm to use for compression.
            0=RLAD (Run-Length Adaptive Dithering (lossy compression).); 1=RLAD_UNIFORM (Run-Length Adaptive Dithering (lossy compression; uniform package size).)
        0x30 DESTINATIONBUFFERLENGTH — Destination buffer length for compressed data.
          [28:0] RLEWORDSMAX
        0x34 START wo reset not defined — Store unit start register
          [0] START — Writing a one starts processing of the pixel engine.
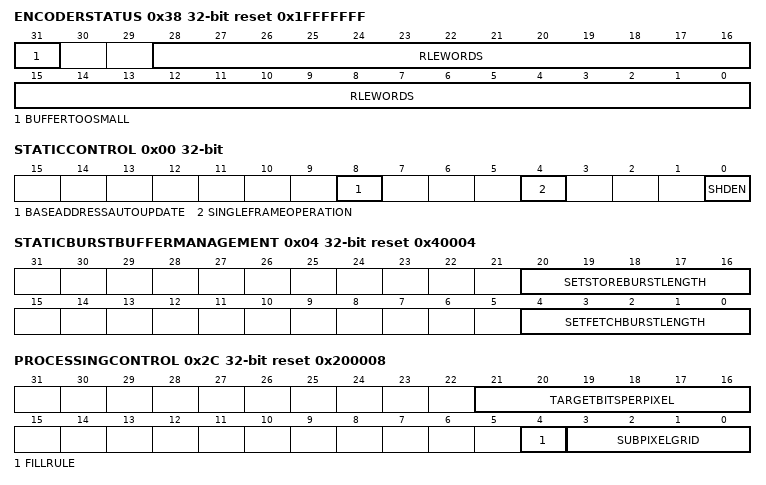
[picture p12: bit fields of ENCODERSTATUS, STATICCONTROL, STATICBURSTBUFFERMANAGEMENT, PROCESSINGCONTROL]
        0x38 ENCODERSTATUS reset 0x1FFFFFFF — Status information of the RLAD encoder.
          [31] BUFFERTOOSMALL — The buffer size given by RLEWordsMax is too small. Not the complete input frame could be encoded.
          [28:0] RLEWORDS ro — Number of 32-bit words minus one that was used for the compressed buffer.
        0x3C WRITEADDRESS ro — Ring buffer synchronization.
          [31:0] WRITEADDRESS — Last burst address that was written to the destination buffer.
        0x40 FRAMEPROPERTIES ro — Ring buffer synchronization.
          [0] FIELDID — Field identifier for interlaced video streams (0/1 = even/odd line indices of progressive frame). Status is updated with begin of a new field.
        0x44 BURSTBUFFERPROPERTIES ro reset not defined — Burst Buffer Property register
          [12:8] MAXBURSTLENGTH — Maximum Burst Length that can be configured.
        0x48 LASTCONTROLWORD ro — Shows the last control word received
          [31:0] L_VAL — Shows the last control word received from the pixel engine. If a 39 bit pixel channel is connected, the mapping is as follows: l_val[31:0] = { data[37:22], data[19:12], data[9:2] }. For debug purposes only, read when stable only, otherwise read data might be corrupted.
        0x4C PERFCOUNTER ro — Performance counter result
          [31:0] PERFRESULT — Returns the performance counter value. Please note that a sw reset during a frame can potentially produce invalid results in the first frame afterwards. For debug purposes only, read when stable only, otherwise read data might be corrupted.
    0x30000 DRAWENG group — Drawing Engine
      0x00 STATICCONTROL reset 0x30 — Drawing Engine static control register
        [5] CLOCKDISABLE — Deactivates most internal clocks of Drawing Engine. Can only be activated if SWReset field is set to SW_RESET.
          0=OPERATION (Normal Operation); 1=POWERDOWN (Clocks are off)
        [4] SWRESET — Puts the Drawing Engine in software reset.
          0=OPERATION (Normal Operation); 1=SW_RESET (Software Reset)
      0x04 STATICBURSTBUFFERMANAGEMENT reset 0x40004 — Burst Buffer setup register
        [20:16] SETSTOREBURSTLENGTH — Set this to the burst length that should be used on the AXI alpha store interface. Please note that SetStoreBurstLength has to be smaller or equal to MaxStoreBurstLength. Only a power of two may be specified as burst length.
        [4:0] SETFETCHBURSTLENGTH — Maximum burst length to be used on the AXI command fetch interface. Has to be 1 in context of VIDEOSSDDR.
      0x08 STATICCMDBUFFERADDRESS — Lowest command buffer address
        [31:0] CMDBUFFERADDRESS — Start address of the command buffer. The address is word aligned, keep bits [1:0] zero. Writing this register resets the CmdBufferReadPtr register.
      0x0C STATICCMDBUFFERSIZE reset 0x1FF — Command buffer size
        [29:0] CMDBUFFERSIZE — Command buffer size in number of 32-bit words. Only power-of-two values are allowed. The value programmed into this field must be one less than the actual number of words.
      0x10 CMDBUFFERWRITEPTR — Buffer end address of command list
        [29:0] CMDBUFFERWRITEPTR — Command buffer write pointer in words. This pointer must be set by the software to one word after the last valid command (start of the next operation).
      0x14 TRANSFORMATIONMATRIXA11 reset 0x10000 — Transformation Matrix.
        [31:0] A11 — Matrix coefficient A11. (format is signed fix-point 16.16)
      0x18 TRANSFORMATIONMATRIXA21 — Transformation Matrix.
        [31:0] A21 — Matrix coefficient A21. (format is signed fix-point 16.16)
      0x1C TRANSFORMATIONMATRIXA12 — Transformation Matrix.
        [31:0] A12 — Matrix coefficient A12. (format is signed fix-point 16.16)
      0x20 TRANSFORMATIONMATRIXA22 reset 0x10000 — Transformation Matrix.
        [31:0] A22 — Matrix coefficient A22. (format is signed fix-point 16.16)
      0x24 TRANSLATIONVECTORX — Horizontal translation of the alpha frame.
        [21:0] TRANSLATIONX — Horizontal translation (X). Fractional part is used for processing. The integer part modifies the XOffset field of the LayerOffset register for subsequent Blit operation. (format is signed fix-point 16.6)
      0x28 TRANSLATIONVECTORY — Vertical translation of the alpha frame.
        [21:0] TRANSLATIONY — Vertical translation (Y). Fractional part is used for processing. The integer part modifies the YOffset field of the LayerOffset register for subsequent Blit operation. (format is signed fix-point 16.6)
      0x2C PROCESSINGCONTROL reset 0x200008 — Drawing Engine main processing control register
        [21:16] TARGETBITSPERPIXEL — Number of bits per pixel in the target buffer for the following blit operation. Must be 1, 2, 4, 8, 16, 18, 24 or 32. This field allows to obtain an aligned bounding box width.
        [4] FILLRULE — Set the fill rule.
          1=NONZERO (a edge count unequal zero is inside); 0=EVENODD (an odd edge count is inside, an even edge count is outside)
        [3:0] SUBPIXELGRID — Higher SubPixelGrid (super sampling) results in better anti-aliased output at the cost of processing time.
          1=TOTALBITS_1 (1 bit per pixel, anti-aliased); 2=TOTALBITS_2 (2 bit per pixel, results in 2 bit anti-aliased intermediate value); 4=TOTALBITS_4 (4 bit per pixel, results in 4 bit anti-aliased intermediate value); 8=TOTALBITS_8 (8 bit per pixel, results in 6 bit anti-aliased intermediate value)
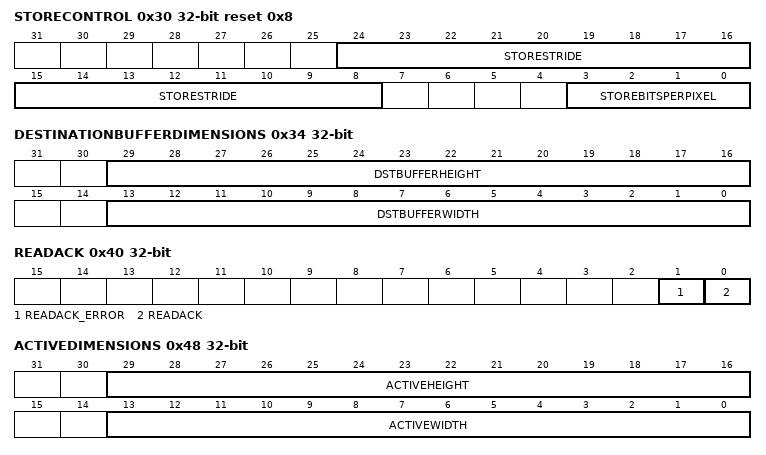
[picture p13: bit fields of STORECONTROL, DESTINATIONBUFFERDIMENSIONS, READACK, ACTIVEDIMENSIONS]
      0x30 STORECONTROL reset 0x8 — Store unit dynamic control register
        [24:8] STORESTRIDE — Destination buffer stride in bytes minus one. Used for address generation.
        [3:0] STOREBITSPERPIXEL — The resulting alpha mask can be saved to memory with the following BitsPerPixel settings.
          1=TOTALBITS_1 (1 bit per pixel); 2=TOTALBITS_2 (2 bit per pixel); 4=TOTALBITS_4 (4 bit per pixel); 8=TOTALBITS_8 (8 bit per pixel)
      0x34 DESTINATIONBUFFERDIMENSIONS — Maximum dimensions of the destination buffer. The resulting alpha frame is limited to this dimensions. However, the active area can be smaller and is given by ActiveDimensions register.
        [29:16] DSTBUFFERHEIGHT — Maximum height of the destination buffer in pixels minus one.
        [13:0] DSTBUFFERWIDTH — Maximum width of the destination buffer in pixels minus one.
      0x38 DESTINATIONBUFFER — Destination buffer base address
        [31:0] DSTBASEADDRESS — Byte aligned start address of the destination buffer.
      0x3C START wo reset not defined — Drawing Engine start register
        [0] START — Writing a one starts processing.
      0x40 READACK wo reset not defined — Drawing Engine read acknowledge register
        [1] READACK_ERROR — Writing a one acknowledges the read of the status register Error.
        [0] READACK — Writing a one acknowledges the read of the status registers ActiveDimensions and Offset.
      0x44 CMDBUFFERREADPTR ro — Buffer end address of command list
        [29:0] CMDBUFFERREADPTR — Command buffer read pointer in words. This pointer is modified by the Drawing Engine hardware and indicates which words are ultimately consumed.
      0x48 ACTIVEDIMENSIONS ro — Shows active dimensions of the output alpha frame. This register is aligned to the ClipWindowDimensions register of the fetch.
        [29:16] ACTIVEHEIGHT — Active height of the resulting alpha frame minus one.
        [13:0] ACTIVEWIDTH — Active width of the resulting alpha frame minus one.
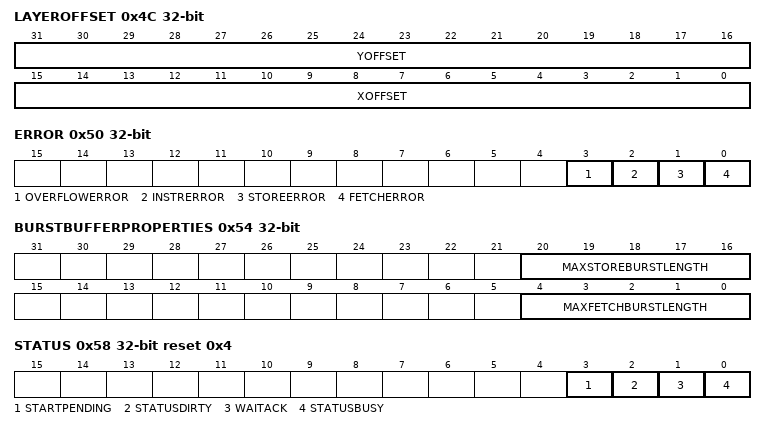
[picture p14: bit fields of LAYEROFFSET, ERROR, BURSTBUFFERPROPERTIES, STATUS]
      0x4C LAYEROFFSET ro — Desired position of the alpha frame for the following Blit operation. This register is aligned to the LayerOffset of the fetch and given as signed 16.0 values.
        [31:16] YOFFSET — Vertical offset (Y). (format is signed integer)
        [15:0] XOFFSET — Horizontal offset (X). (format is signed integer)
      0x50 ERROR ro — Error status of finished operation. If register is unequal to zero the resulting raster image is most likely corrupted.
        [3] OVERFLOWERROR — Indicates if an overflow occurred when truncating to internal data width.
        [2] INSTRERROR — Indicates if the command list contained an illegal or unexpected instruction.
        [1] STOREERROR — Indicates if storing the alpha bitmap to memory failed.
        [0] FETCHERROR — Indicates if an bus error occurred while fetching the command list.
      0x54 BURSTBUFFERPROPERTIES ro reset not defined — Burst Buffer Property register
        [20:16] MAXSTOREBURSTLENGTH — Maximum Burst Length that can be configured for alpha store.
        [4:0] MAXFETCHBURSTLENGTH — Maximum Burst Length that can be configured for command fetch.
      0x58 STATUS ro reset 0x4 — Status bits.
        [3] STARTPENDING — Indicates if another start trigger is pending.
        [2] STATUSDIRTY — Indicates if the linebuffer memory requires a clear prior to the next drawing operation.
        [1] WAITACK — Indicates if Drawing Engine is waiting on an read acknowledge.
        [0] STATUSBUSY — Indicates if Drawing Engine is busy with drawing a command list.
      0x5C PERFCOUNTERFRONT ro — Performance counter result
        [31:0] PERFRESULTFRONT — Returns the performance counter value of the front pipeline. For the total cycle count add PerfResultFront and PerfResultBack. For debug purposes only, read when stable only.
      0x60 PERFCOUNTERBACK ro — Performance counter result
        [31:0] PERFRESULTBACK — Returns the performance counter value of the back pipeline. For the total cycle count add PerfResultFront and PerfResultBack. For debug purposes only, read when stable only.
